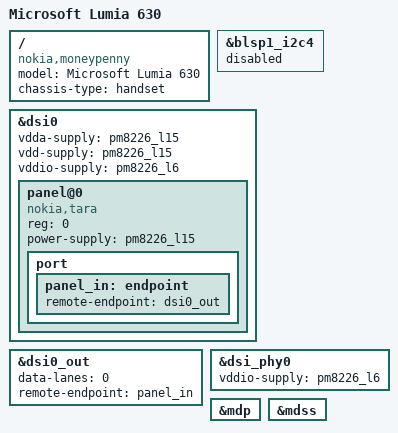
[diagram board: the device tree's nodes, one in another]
// SPDX-License-Identifier: BSD-3-Clause
/*
 * Copyright (c) 2022, Jack Matthews <jm5112356@gmail.com>
 * Copyright (c) 2022, Ivaylo Ivanov <ivo.ivanov.ivanov1@gmail.com>
 * Copyright (c) 2022, Dominik Kobinski <dominikkobinski314@gmail.com>
 * Copyright (c) 2022, Rayyan Ansari <rayyan@ansari.sh>
 */

/dts-v1/;

#include "qcom-msm8226-nokia-common.dtsi"

/ {
	model = "Microsoft Lumia 630";
	compatible = "nokia,moneypenny", "qcom,msm8226";
	chassis-type = "handset";
};

&blsp1_i2c4 {
	status = "disabled";
	/delete-node/ qpdst900@39;
};

&dsi0 {
	status = "okay";

	vdda-supply = <&pm8226_l15>;
	vdd-supply = <&pm8226_l15>;
	vddio-supply = <&pm8226_l6>;

	panel@0 {
		compatible = "nokia,tara";
		reg = <0>;

		power-supply = <&pm8226_l15>;

		port {
			panel_in: endpoint {
				remote-endpoint = <&dsi0_out>;
			};
		};
	};
};

&dsi0_out {
	data-lanes = <0>;
	remote-endpoint = <&panel_in>;
};

&dsi_phy0 {
	status = "okay";
	
	vddio-supply = <&pm8226_l6>;
};

&mdp {
	status = "okay";
};

&mdss {
	status = "okay";
};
